# jbr_MDR1986VE1T register map
Registers are 32-bit, access not given, no defined reset value unless marked. A register's access mark holds for its fields unless they carry their own. Addresses are absolute; registers are grouped by the start of their names; [hi:lo] are bit positions; {n}, {i} and the like mark numbered series; 'fields as' and 'values as' point back to an identical list.

## CAN2
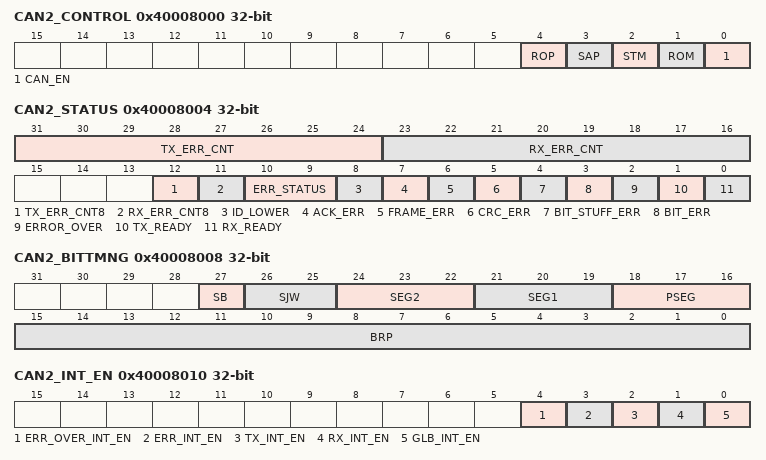
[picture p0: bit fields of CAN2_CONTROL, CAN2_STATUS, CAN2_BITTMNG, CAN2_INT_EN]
0x40008000 CAN2_CONTROL
  [4] ROP, [3] SAP, [2] STM, [1] ROM, [0] CAN_EN
0x40008004 CAN2_STATUS
  [31:24] TX_ERR_CNT, [23:16] RX_ERR_CNT, [12] TX_ERR_CNT8, [11] RX_ERR_CNT8, [10:9] ERR_STATUS, [8] ID_LOWER, [7] ACK_ERR, [6] FRAME_ERR, [5] CRC_ERR, [4] BIT_STUFF_ERR, [3] BIT_ERR, [2] ERROR_OVER, [1] TX_READY, [0] RX_READY
0x40008008 CAN2_BITTMNG
  [27] SB, [26:25] SJW, [24:22] SEG2, [21:19] SEG1, [18:16] PSEG, [15:0] BRP
0x40008010 CAN2_INT_EN
  [4] ERR_OVER_INT_EN, [3] ERR_INT_EN, [2] TX_INT_EN, [1] RX_INT_EN, [0] GLB_INT_EN
0x4000801C CAN2_OVER
  [7:0] ERROR_MAX
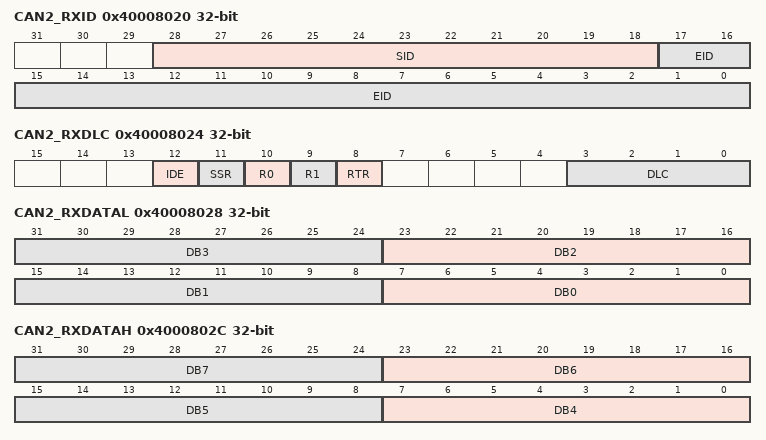
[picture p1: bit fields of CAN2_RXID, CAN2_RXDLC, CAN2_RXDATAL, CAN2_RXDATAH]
0x40008020 CAN2_RXID
  [28:18] SID, [17:0] EID
0x40008024 CAN2_RXDLC
  [12] IDE, [11] SSR, [10] R0, [9] R1, [8] RTR, [3:0] DLC
0x40008028 CAN2_RXDATAL
  [8n+7:8n] DB{n} (n=0..3)
0x4000802C CAN2_RXDATAH
  [8n-25:8n-32] DB{n} (n=4..7)
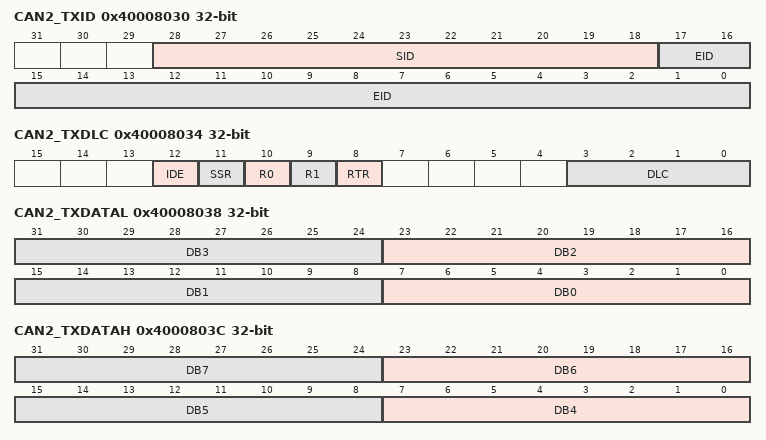
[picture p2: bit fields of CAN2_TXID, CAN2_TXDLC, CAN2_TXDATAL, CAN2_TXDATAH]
0x40008030 CAN2_TXID
  [28:18] SID, [17:0] EID
0x40008034 CAN2_TXDLC
  [12] IDE, [11] SSR, [10] R0, [9] R1, [8] RTR, [3:0] DLC
0x40008038 CAN2_TXDATAL
  [8n+7:8n] DB{n} (n=0..3)
0x4000803C CAN2_TXDATAH
  [8n-25:8n-32] DB{n} (n=4..7)
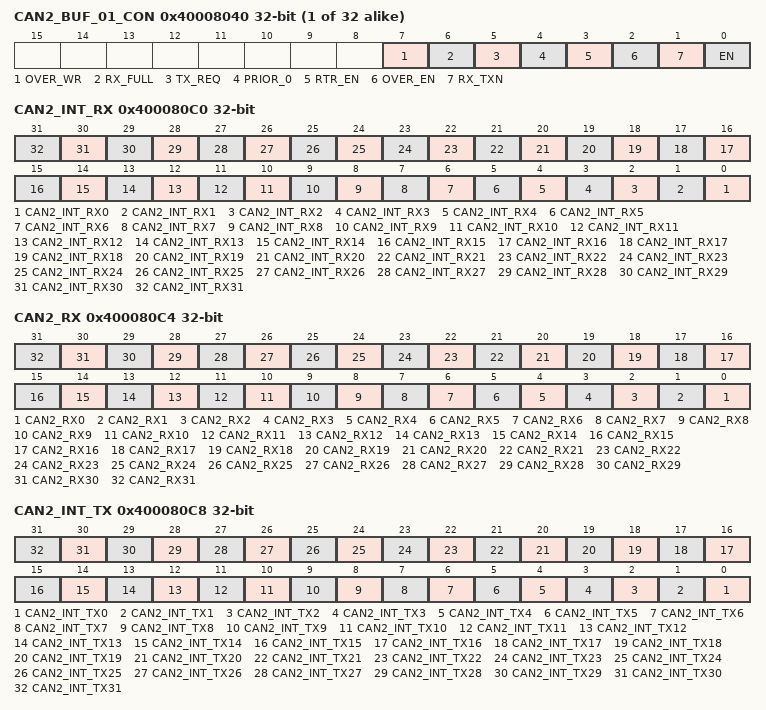
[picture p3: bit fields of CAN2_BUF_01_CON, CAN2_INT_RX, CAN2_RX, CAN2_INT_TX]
{0x4000803C+4i} CAN2_BUF_{i:02}_CON (i=1..32)
  [7] OVER_WR, [6] RX_FULL, [5] TX_REQ, [4] PRIOR_0, [3] RTR_EN, [2] OVER_EN, [1] RX_TXN, [0] EN
0x400080C0 CAN2_INT_RX
  [n] CAN2_INT_RX{n} (n=0..31)
0x400080C4 CAN2_RX
  [n] CAN2_RX{n} (n=0..31)
0x400080C8 CAN2_INT_TX
  [n] CAN2_INT_TX{n} (n=0..31)
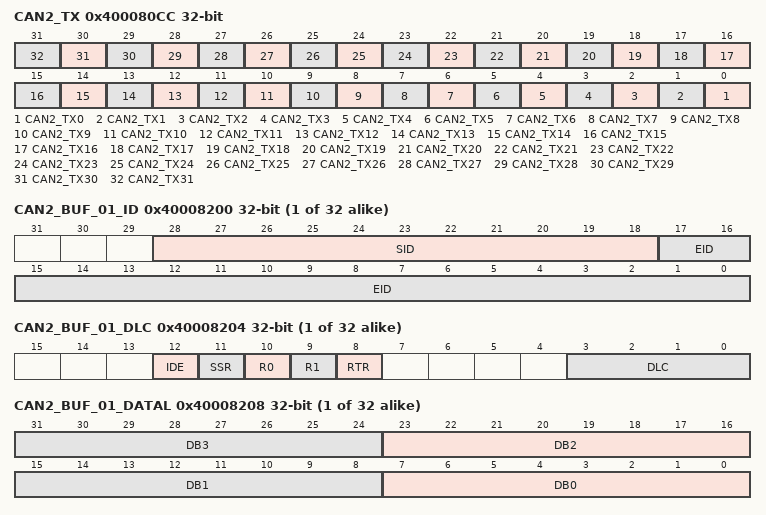
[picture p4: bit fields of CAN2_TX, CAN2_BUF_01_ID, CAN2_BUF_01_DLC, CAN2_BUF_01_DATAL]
0x400080CC CAN2_TX
  [n] CAN2_TX{n} (n=0..31)
{0x400081F0+0x10*i} CAN2_BUF_{i:02}_ID (i=1..32)
  [28:18] SID, [17:0] EID
{0x400081F4+0x10*i} CAN2_BUF_{i:02}_DLC (i=1..32)
  [12] IDE, [11] SSR, [10] R0, [9] R1, [8] RTR, [3:0] DLC
{0x400081F8+0x10*i} CAN2_BUF_{i:02}_DATAL (i=1..32)
  [8n+7:8n] DB{n} (n=0..3)
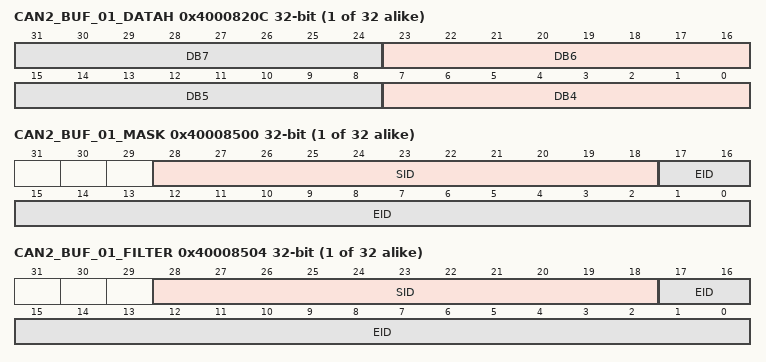
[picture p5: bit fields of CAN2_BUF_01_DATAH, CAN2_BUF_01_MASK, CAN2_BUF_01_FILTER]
{0x400081FC+0x10*i} CAN2_BUF_{i:02}_DATAH (i=1..32)
  [8n-25:8n-32] DB{n} (n=4..7)
0x40008320 CAN2_BUF_29_ID
{0x400084F8+8i} CAN2_BUF_{i:02}_MASK (i=1..32)
  [28:18] SID, [17:0] EID
{0x400084FC+8i} CAN2_BUF_{i:02}_FILTER (i=1..32)
  [28:18] SID, [17:0] EID

## TIM1
0x40070000 TIM1_CNT
0x40070004 TIM1_PSG
  [15:0] PSG
0x40070008 TIM1_ARR
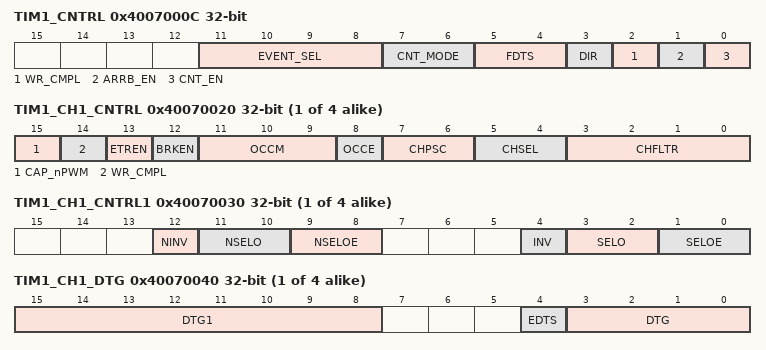
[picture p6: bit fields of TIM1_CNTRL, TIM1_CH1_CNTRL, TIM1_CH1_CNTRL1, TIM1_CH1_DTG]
0x4007000C TIM1_CNTRL
  [11:8] EVENT_SEL, [7:6] CNT_MODE, [5:4] FDTS, [3] DIR, [2] WR_CMPL, [1] ARRB_EN, [0] CNT_EN
{0x4007000C+4i} TIM1_CCR{i} (i=1..4)
  [31:0] CCR
{0x4007001C+4i} TIM1_CH{i}_CNTRL (i=1..4)
  [15] CAP_nPWM, [14] WR_CMPL, [13] ETREN, [12] BRKEN, [11:9] OCCM, [8] OCCE, [7:6] CHPSC, [5:4] CHSEL, [3:0] CHFLTR
{0x4007002C+4i} TIM1_CH{i}_CNTRL1 (i=1..4)
  [12] NINV, [11:10] NSELO, [9:8] NSELOE, [4] INV, [3:2] SELO, [1:0] SELOE
{0x4007003C+4i} TIM1_CH{i}_DTG (i=1..4)
  [15:8] DTG1, [4] EDTS, [3:0] DTG
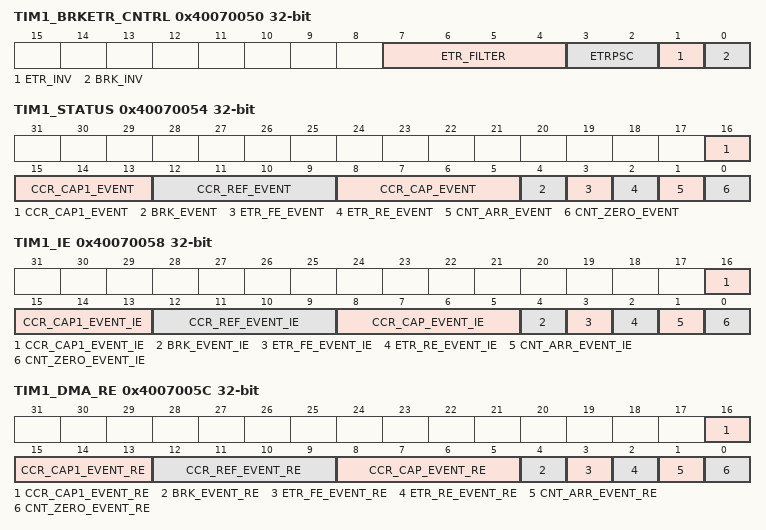
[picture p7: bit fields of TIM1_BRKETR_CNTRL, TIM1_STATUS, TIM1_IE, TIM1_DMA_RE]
0x40070050 TIM1_BRKETR_CNTRL
  [7:4] ETR_FILTER, [3:2] ETRPSC, [1] ETR_INV, [0] BRK_INV
0x40070054 TIM1_STATUS
  [16:13] CCR_CAP1_EVENT, [12:9] CCR_REF_EVENT, [8:5] CCR_CAP_EVENT, [4] BRK_EVENT, [3] ETR_FE_EVENT, [2] ETR_RE_EVENT, [1] CNT_ARR_EVENT, [0] CNT_ZERO_EVENT
0x40070058 TIM1_IE
  [16:13] CCR_CAP1_EVENT_IE, [12:9] CCR_REF_EVENT_IE, [8:5] CCR_CAP_EVENT_IE, [4] BRK_EVENT_IE, [3] ETR_FE_EVENT_IE, [2] ETR_RE_EVENT_IE, [1] CNT_ARR_EVENT_IE, [0] CNT_ZERO_EVENT_IE
0x4007005C TIM1_DMA_RE
  [16:13] CCR_CAP1_EVENT_RE, [12:9] CCR_REF_EVENT_RE, [8:5] CCR_CAP_EVENT_RE, [4] BRK_EVENT_RE, [3] ETR_FE_EVENT_RE, [2] ETR_RE_EVENT_RE, [1] CNT_ARR_EVENT_RE, [0] CNT_ZERO_EVENT_RE
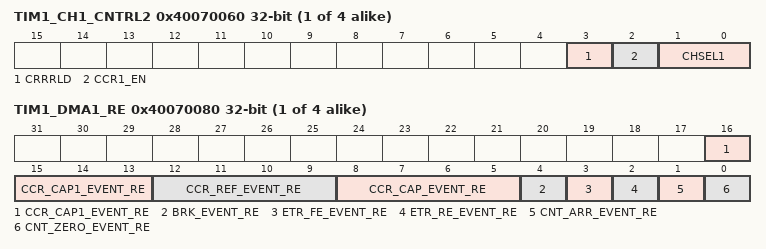
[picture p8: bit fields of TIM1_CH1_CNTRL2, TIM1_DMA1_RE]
{0x4007005C+4i} TIM1_CH{i}_CNTRL2 (i=1..4)
  [3] CRRRLD, [2] CCR1_EN, [1:0] CHSEL1
0x40070070 TIM1_CCR11
  [31:0] CCR1
0x40070074 TIM1_CCR21
  [31:0] CCR1
0x40070078 TIM1_CCR31
  [31:0] CCR1
0x4007007C TIM1_CCR41
  [31:0] CCR1
{0x4007007C+4i} TIM1_DMA{i}_RE (i=1..4)
  fields as TIM1_DMA_RE

## TIM2
0x40078000 TIM2_CNT
0x40078004 TIM2_PSG
  [15:0] PSG
0x40078008 TIM2_ARR
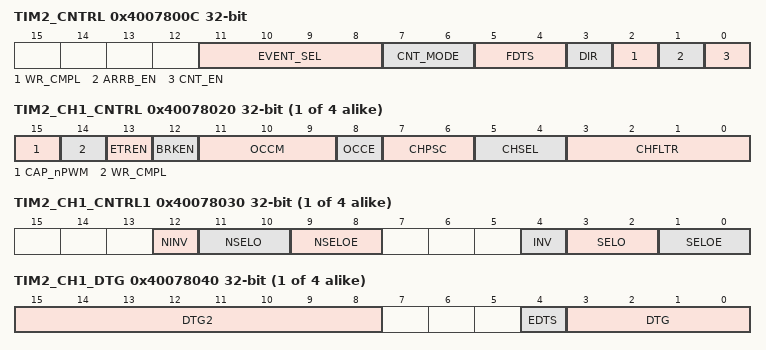
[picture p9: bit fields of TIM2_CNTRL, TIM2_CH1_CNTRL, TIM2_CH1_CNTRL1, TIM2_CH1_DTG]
0x4007800C TIM2_CNTRL
  [11:8] EVENT_SEL, [7:6] CNT_MODE, [5:4] FDTS, [3] DIR, [2] WR_CMPL, [1] ARRB_EN, [0] CNT_EN
{0x4007800C+4i} TIM2_CCR{i} (i=1..4)
  [31:0] CCR
{0x4007801C+4i} TIM2_CH{i}_CNTRL (i=1..4)
  [15] CAP_nPWM, [14] WR_CMPL, [13] ETREN, [12] BRKEN, [11:9] OCCM, [8] OCCE, [7:6] CHPSC, [5:4] CHSEL, [3:0] CHFLTR
{0x4007802C+4i} TIM2_CH{i}_CNTRL1 (i=1..4)
  [12] NINV, [11:10] NSELO, [9:8] NSELOE, [4] INV, [3:2] SELO, [1:0] SELOE
{0x4007803C+4i} TIM2_CH{i}_DTG (i=1..4)
  [15:8] DTG2, [4] EDTS, [3:0] DTG
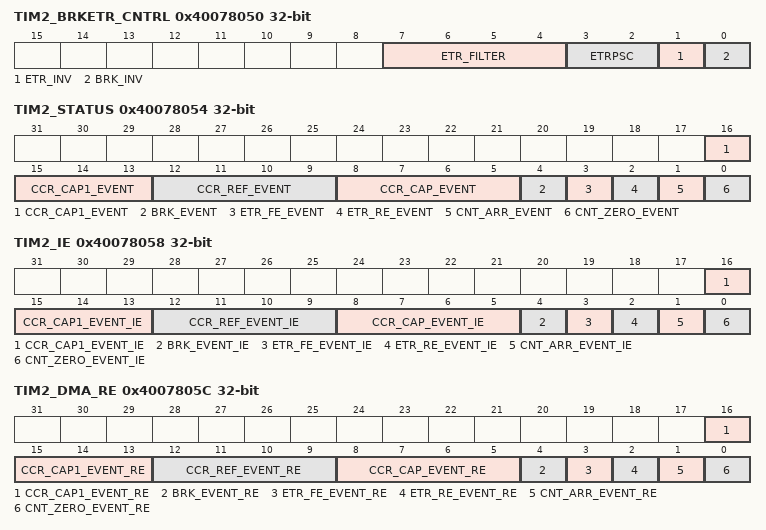
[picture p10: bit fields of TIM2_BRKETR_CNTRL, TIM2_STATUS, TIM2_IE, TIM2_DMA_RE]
0x40078050 TIM2_BRKETR_CNTRL
  [7:4] ETR_FILTER, [3:2] ETRPSC, [1] ETR_INV, [0] BRK_INV
0x40078054 TIM2_STATUS
  [16:13] CCR_CAP1_EVENT, [12:9] CCR_REF_EVENT, [8:5] CCR_CAP_EVENT, [4] BRK_EVENT, [3] ETR_FE_EVENT, [2] ETR_RE_EVENT, [1] CNT_ARR_EVENT, [0] CNT_ZERO_EVENT
0x40078058 TIM2_IE
  [16:13] CCR_CAP1_EVENT_IE, [12:9] CCR_REF_EVENT_IE, [8:5] CCR_CAP_EVENT_IE, [4] BRK_EVENT_IE, [3] ETR_FE_EVENT_IE, [2] ETR_RE_EVENT_IE, [1] CNT_ARR_EVENT_IE, [0] CNT_ZERO_EVENT_IE
0x4007805C TIM2_DMA_RE
  [16:13] CCR_CAP1_EVENT_RE, [12:9] CCR_REF_EVENT_RE, [8:5] CCR_CAP_EVENT_RE, [4] BRK_EVENT_RE, [3] ETR_FE_EVENT_RE, [2] ETR_RE_EVENT_RE, [1] CNT_ARR_EVENT_RE, [0] CNT_ZERO_EVENT_RE
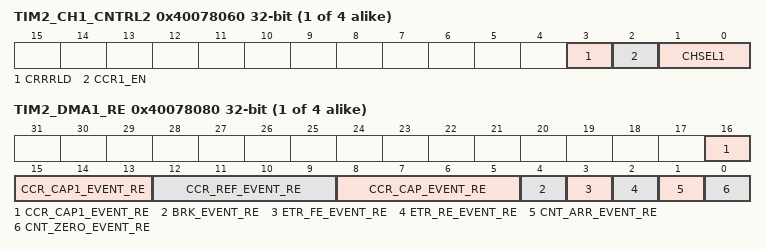
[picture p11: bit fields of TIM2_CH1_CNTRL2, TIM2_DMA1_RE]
{0x4007805C+4i} TIM2_CH{i}_CNTRL2 (i=1..4)
  [3] CRRRLD, [2] CCR1_EN, [1:0] CHSEL1
0x40078070 TIM2_CCR11
  [31:0] CCR1
0x40078074 TIM2_CCR21
  [31:0] CCR1
0x40078078 TIM2_CCR31
  [31:0] CCR1
0x4007807C TIM2_CCR41
  [31:0] CCR1
{0x4007807C+4i} TIM2_DMA{i}_RE (i=1..4)
  fields as TIM2_DMA_RE
